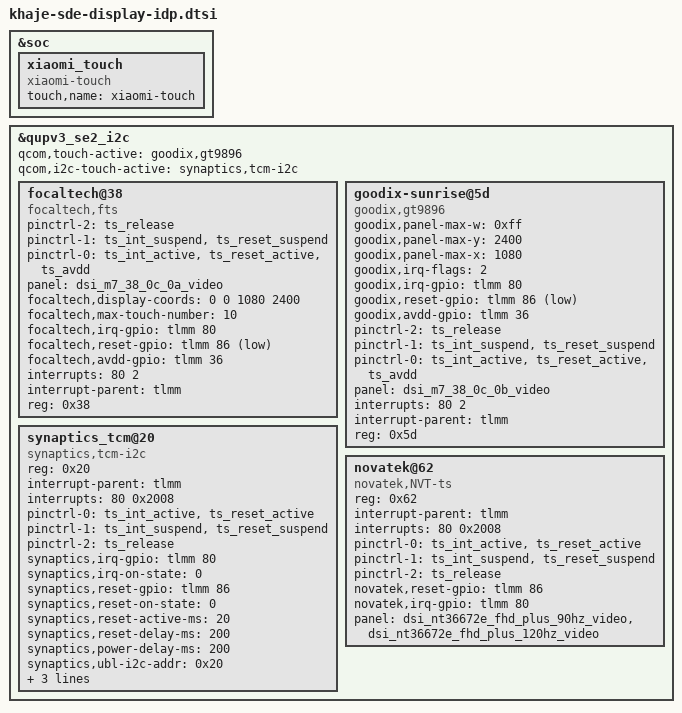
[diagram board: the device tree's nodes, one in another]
#include "khaje-sde-display.dtsi"
/*&dsi_td4330_truly_v2_video {
	qcom,panel-supply-entries = <&dsi_panel_pwr_supply_no_labibb>;
	qcom,mdss-dsi-bl-pmic-control-type = "bl_ctrl_pwm";
	pwms = <&pm6125_pwm 0 0>;
	qcom,bl-pmic-pwm-period-usecs = <100>;
	qcom,mdss-dsi-bl-min-level = <1>;
	qcom,mdss-dsi-bl-max-level = <4095>;
	qcom,platform-reset-gpio = <&tlmm 82 0>;
};

&dsi_td4330_truly_v2_cmd {
	qcom,panel-supply-entries = <&dsi_panel_pwr_supply_no_labibb>;
	qcom,mdss-dsi-bl-pmic-control-type = "bl_ctrl_pwm";
	pwms = <&pm6125_pwm 0 0>;
	qcom,bl-pmic-pwm-period-usecs = <100>;
	qcom,mdss-dsi-bl-min-level = <1>;
	qcom,mdss-dsi-bl-max-level = <4095>;
	qcom,platform-te-gpio = <&tlmm 81 0>;
	qcom,platform-reset-gpio = <&tlmm 82 0>;
};

&dsi_nt36672e_fhd_plus_90hz_video {
	qcom,panel-supply-entries = <&dsi_panel_pwr_supply_no_labibb>;
	qcom,mdss-dsi-bl-pmic-control-type = "bl_ctrl_pwm";
	pwms = <&pm6125_pwm 0 0>;
	qcom,bl-pmic-pwm-period-usecs = <100>;
	qcom,mdss-dsi-bl-min-level = <1>;
	qcom,mdss-dsi-bl-max-level = <4095>;
	qcom,platform-reset-gpio = <&tlmm 82 0>;
};

&dsi_nt36672e_fhd_plus_120hz_video {
	qcom,panel-supply-entries = <&dsi_panel_pwr_supply_no_labibb>;
	qcom,mdss-dsi-bl-pmic-control-type = "bl_ctrl_pwm";
	pwms = <&pm6125_pwm 0 0>;
	qcom,bl-pmic-pwm-period-usecs = <100>;
	qcom,mdss-dsi-bl-min-level = <1>;
	qcom,mdss-dsi-bl-max-level = <4095>;
	qcom,platform-reset-gpio = <&tlmm 82 0>;
};

&dsi_sim_vid {
	qcom,panel-supply-entries = <&dsi_panel_pwr_supply_no_labibb>;
	qcom,mdss-dsi-bl-pmic-control-type = "bl_ctrl_dcs";
	qcom,platform-reset-gpio = <&tlmm 82 0>;
};

&sde_dsi {
	qcom,dsi-default-panel = <&dsi_td4330_truly_v2_video>;
};*/

&soc {
    xiaomi_touch {
        compatible = "xiaomi-touch";
        touch,name = "xiaomi-touch";
        status = "okay";
    };
};

&qupv3_se2_i2c {
    qcom,touch-active = "goodix,gt9896";
	qcom,i2c-touch-active = "focaltech,fts";
	status = "okay";

	focaltech@38 {
			pinctrl-2 = <&ts_release>;
			pinctrl-1 = <&ts_int_suspend
                         &ts_reset_suspend>;
			pinctrl-0 = <&ts_int_active
                         &ts_reset_active
                         &ts_avdd>;
			pinctrl-names = "pmx_ts_active\0pmx_ts_suspend\0pmx_ts_release";
			panel = <&dsi_m7_38_0c_0a_video>;
			focaltech,display-coords = <0 0 1080 2400>;
			focaltech,max-touch-number = <10>;
			focaltech,irq-gpio = <&tlmm 80 2>;
			focaltech,reset-gpio = <&tlmm 86 1>;
			focaltech,avdd-gpio = <&tlmm 36 0>;
			interrupts = <80 2>;
			interrupt-parent = <&tlmm>;
			reg = <0x38>;
			compatible = "focaltech,fts";
			status = "okay";
	};

	goodix-sunrise@5d {
			goodix,panel-max-w = <0xff>;
			goodix,panel-max-y = <2400>;
			goodix,panel-max-x = <1080>;
			goodix,irq-flags = <2>;
			goodix,irq-gpio = <&tlmm 80 2>;
			goodix,reset-gpio = <&tlmm 86 1>;
			goodix,avdd-gpio = <&tlmm 36 0>;
			pinctrl-2 = <&ts_release>;
			pinctrl-1 = <&ts_int_suspend
                         &ts_reset_suspend>;
			pinctrl-0 = <&ts_int_active
                         &ts_reset_active
                         &ts_avdd>;
			pinctrl-names = "pmx_ts_active\0pmx_ts_suspend\0pmx_ts_release";
			panel = <&dsi_m7_38_0c_0b_video>;
			interrupts = <80 2>;
			interrupt-parent = <&tlmm>;
			reg = <0x5d>;
			compatible = "goodix,gt9896";
			status = "okay";
	};
};

&qupv3_se2_i2c {
	status = "okay";
	qcom,i2c-touch-active="synaptics,tcm-i2c";

	synaptics_tcm@20 {
		compatible = "synaptics,tcm-i2c";
		reg = <0x20>;
		interrupt-parent = <&tlmm>;
		interrupts = <80 0x2008>;
		pinctrl-names = "pmx_ts_active","pmx_ts_suspend",
			"pmx_ts_release";
		pinctrl-0 = <&ts_int_active &ts_reset_active>;
		pinctrl-1 = <&ts_int_suspend &ts_reset_suspend>;
		pinctrl-2 = <&ts_release>;
		synaptics,irq-gpio = <&tlmm 80 0x2008>;
		synaptics,irq-on-state = <0>;
		synaptics,reset-gpio = <&tlmm 86 0x00>;
		synaptics,reset-on-state = <0>;
		synaptics,reset-active-ms = <20>;
		synaptics,reset-delay-ms = <200>;
		synaptics,power-delay-ms = <200>;
		synaptics,ubl-i2c-addr = <0x20>;
		synaptics,extend_report;
		synaptics,firmware-name = "synaptics_firmware_k.img";

		//panel = <&dsi_td4330_truly_v2_video &dsi_td4330_truly_v2_cmd>;
	};

	novatek@62 {
		compatible = "novatek,NVT-ts";
		reg = <0x62>;
		status = "ok";

		interrupt-parent = <&tlmm>;
		interrupts = <80 0x2008>;
		pinctrl-names = "pmx_ts_active","pmx_ts_suspend",
			"pmx_ts_release";
		pinctrl-0 = <&ts_int_active &ts_reset_active>;
		pinctrl-1 = <&ts_int_suspend &ts_reset_suspend>;
		pinctrl-2 = <&ts_release>;

		novatek,reset-gpio = <&tlmm 86 0x00>;
		novatek,irq-gpio = <&tlmm 80 0x2008>;

		panel = <&dsi_nt36672e_fhd_plus_90hz_video
			&dsi_nt36672e_fhd_plus_120hz_video>;
	};
};
